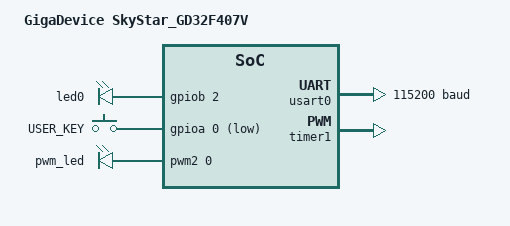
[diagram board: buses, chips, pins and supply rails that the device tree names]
/*
 * Copyright (c) 2025, Liu Changjie <liucj1228@outlook.com>
 * SPDX-License-Identifier: Apache-2.0
 */

/dts-v1/;

#include <gd/gd32f4xx/gd32f407xk.dtsi>
#include "skystar_gd32f407v-pinctrl.dtsi"
#include <zephyr/dt-bindings/input/input-event-codes.h>

/ {
	model = "GigaDevice SkyStar_GD32F407V";
	compatible = "gd,skystar_gd32f407v";

	chosen {
		zephyr,sram = &sram0;
		zephyr,flash = &flash0;
		zephyr,console = &usart0;
		zephyr,shell-uart = &usart0;
	};

	leds {
		compatible = "gpio-leds";

		led0: led0 {
			gpios = <&gpiob 2 GPIO_ACTIVE_HIGH>;
		};
	};

	gpio_keys {
		compatible = "gpio-keys";

		user_key: user_key {
			label = "USER_KEY";
			gpios = <&gpioa 0 GPIO_ACTIVE_LOW>;
			zephyr,code = <INPUT_KEY_0>;
		};
	};

	pwmleds {
		compatible = "pwm-leds";

		pwm_led: pwm_led {
			pwms = <&pwm2 0 PWM_MSEC(20) PWM_POLARITY_NORMAL>;
		};
	};

	aliases {
		led0 = &led0;
		sw0 = &user_key;
		pwm-led0 = &pwm_led;
	};
};

&gpioa {
	status = "okay";
};

&gpiob {
	status = "okay";
};

&usart0 {
	status = "okay";
	current-speed = <115200>;
	pinctrl-0 = <&usart0_default>;
	pinctrl-names = "default";
};

&timer1 {
	status = "okay";
	prescaler = <168>;

	pwm2: pwm {
		status = "okay";
		pinctrl-0 = <&pwm2_default>;
		pinctrl-names = "default";
	};
};
